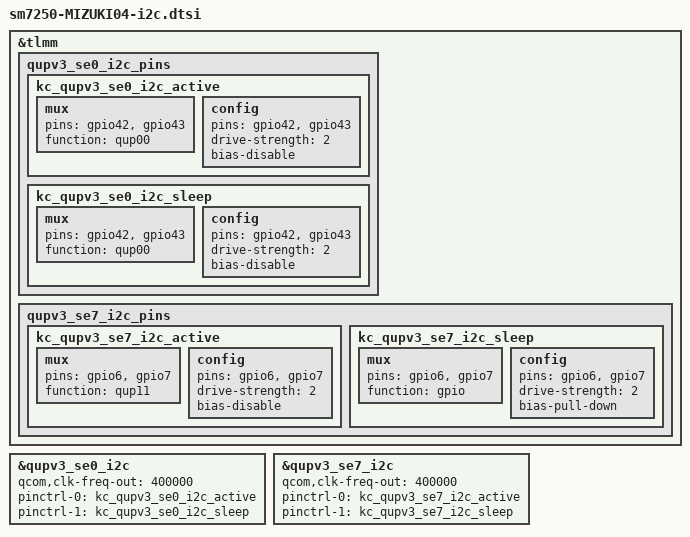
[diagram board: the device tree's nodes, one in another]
/*
 * This software is contributed or developed by KYOCERA Corporation.
 * (C) 2021 KYOCERA Corporation
 *
 * This program is free software; you can redistribute it and/or modify
 * it under the terms of the GNU General Public License version 2 and
 * only version 2 as published by the Free Software Foundation.
 *
 * This program is distributed in the hope that it will be useful,
 * but WITHOUT ANY WARRANTY; without even the implied warranty of
 * MERCHANTABILITY or FITNESS FOR A PARTICULAR PURPOSE.  See the
 * GNU General Public License for more details.
 */

&tlmm {
    qupv3_se0_i2c_pins {
        kc_qupv3_se0_i2c_active: kc_qupv3_se0_i2c_active {
            mux {
                pins = "gpio42", "gpio43";
                function = "qup00";
            };
            config {
                pins = "gpio42", "gpio43";
                drive-strength = <2>;
                bias-disable;
            };
        };
        kc_qupv3_se0_i2c_sleep: kc_qupv3_se0_i2c_sleep {
            mux {
                pins = "gpio42", "gpio43";
                function = "qup00";
            };
            config {
                pins = "gpio42", "gpio43";
                drive-strength = <2>;
                bias-disable;
            };
        };
    };

    qupv3_se7_i2c_pins {
        kc_qupv3_se7_i2c_active: kc_qupv3_se7_i2c_active {
            mux {
                pins = "gpio6", "gpio7";
                function = "qup11";
            };
            config {
                pins = "gpio6", "gpio7";
                drive-strength = <2>;
                bias-disable;
            };
        };
        kc_qupv3_se7_i2c_sleep: kc_qupv3_se7_i2c_sleep {
            mux {
                pins = "gpio6", "gpio7";
                function = "gpio";
            };
            config {
                pins = "gpio6", "gpio7";
                drive-strength = <2>;
                bias-pull-down;
            };
        };
    };
};

&qupv3_se0_i2c {
    qcom,clk-freq-out = <400000>;
    pinctrl-0 = <&kc_qupv3_se0_i2c_active>;
    pinctrl-1 = <&kc_qupv3_se0_i2c_sleep>;
    status = "ok";
};

&qupv3_se7_i2c {
    qcom,clk-freq-out = <400000>;
    pinctrl-0 = <&kc_qupv3_se7_i2c_active>;
    pinctrl-1 = <&kc_qupv3_se7_i2c_sleep>;
    status = "ok";
};
